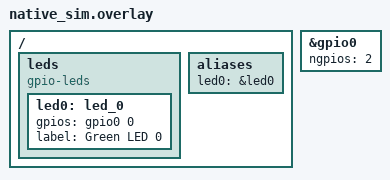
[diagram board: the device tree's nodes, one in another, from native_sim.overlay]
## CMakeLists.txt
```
cmake_minimum_required(VERSION 3.20.0)

find_package(Zephyr REQUIRED HINTS $ENV{ZEPHYR_BASE})
project(led_thread_test)

# add location_module (the unit under test)
target_sources(app
    PRIVATE 
    ../../../app/src/modules/led/led_thread.c
    ../../../app/src/common/zbus_channels.c
)

zephyr_include_directories(${ZEPHYR_BASE}/include/zephyr/)
zephyr_include_directories(${ZEPHYR_BASE}/subsys/testsuite/include)
target_include_directories(app PRIVATE ../../../app/src/common)

target_link_options(app PRIVATE --whole-archive)
# Options that cannot be passed through Kconfig fragments
target_compile_definitions(app PRIVATE
	-DCONFIG_APP_LED_LOG_LEVEL=4
	-DCONFIG_APP_LED_THREAD_STACK_SIZE=1024
	-DCONFIG_APP_LED_MSGQ_SIZE=5
	-DCONFIG_APP_LED_WATCHDOG_TIMEOUT_SECONDS=10
	-DCONFIG_APP_LED_MSGQ_TIMEOUT_SECONDS=5
)

# add test file
target_sources(app PRIVATE src/test_led_thread.c)
```

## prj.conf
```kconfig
#
# Copyright (c) 2022 Nordic Semiconductor ASA
#
# SPDX-License-Identifier: LicenseRef-Nordic-5-Clause
#
CONFIG_ZTEST=y

# Task Watchdog
CONFIG_TASK_WDT=y
CONFIG_TASK_WDT_CHANNELS=5
CONFIG_TASK_WDT_MIN_TIMEOUT=10000

# Configure Zbus
CONFIG_ZBUS=y
CONFIG_ZBUS_LOG_LEVEL_DBG=y

# Configure Emulation
CONFIG_EMUL=y
CONFIG_GPIO=y
CONFIG_GPIO_EMUL=y
CONFIG_GPIO_GET_DIRECTION=y

# Configure Logging
CONFIG_LOG=y
CONFIG_ASSERT=y
CONFIG_BOOT_BANNER=n
```

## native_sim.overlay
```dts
/*
 * Copyright (c) 2021 Nordic Semiconductor ASA
 * SPDX-License-Identifier: Apache-2.0
 */

/* This devicetree overlay file will be automatically picked by the Zephyr
 * build system when building the sample for the nrf52840dk board. It shows
 * how the example-application can be built on sample boards already provided
 * by Zephyr.
 */

/ {
    leds {
		compatible = "gpio-leds";
		led0: led_0 {
			gpios = <&gpio0 0 GPIO_ACTIVE_HIGH>;
			label = "Green LED 0";
		};
	};

    aliases {
		led0 = &led0;
	};
};

&gpio0 {
	status = "okay";
	ngpios = <2>;
};
```

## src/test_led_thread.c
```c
#include <zephyr/irq_offload.h>
#include <zephyr/kernel.h>
#include <zephyr/logging/log.h>
#include <zephyr/zbus/zbus.h>
#include <zephyr/ztest.h>
#include <zephyr/drivers/gpio/gpio_emul.h>

#include "zbus_channels.h"

LOG_MODULE_REGISTER( test_led_thread, LOG_LEVEL_DBG );

// The devicetree node identifier for the "led0" alias.
#define LED0_NODE DT_ALIAS( led0 )
#if !DT_NODE_HAS_STATUS_OKAY( LED0_NODE )
#error "Unsupported board: led0 devicetree alias is not defined"
#endif
static const struct gpio_dt_spec led = GPIO_DT_SPEC_GET( LED0_NODE, gpios );

ZTEST( integration, test_button_press )
{
    struct button_msg button_message = { .press = BUTTON_PRESS };
    int               gpio_val       = -1;

    // Wait for the led to be configured as an output by the thread under test
    while( gpio_pin_is_output_dt( &led ) == 0 )
    {
        k_sleep( K_MSEC( 10 ) );
    }

    // Simulate a button press by publishing to the channel and check the LED value
    zbus_chan_pub( &BUTTON_CHAN, &button_message, K_FOREVER );
    k_sleep( K_MSEC( 100 ) );
    gpio_val = gpio_emul_output_get( led.port, led.pin );
    zassert_equal( gpio_val, 1, "LED state should be ON (1), observed (%d)", gpio_val );
}

ZTEST( integration, test_button_release )
{
    struct button_msg button_message = { .press = BUTTON_RELEASE };
    int               gpio_val       = -1;

    // Wait for the led to be configured as an output by the thread under test
    while( gpio_pin_is_output_dt( &led ) == 0 )
    {
        k_sleep( K_MSEC( 10 ) );
    }

    // Simulate a button press by publishing to the channel and check the LED value
    zbus_chan_pub( &BUTTON_CHAN, &button_message, K_FOREVER );
    k_sleep( K_MSEC( 100 ) );
    gpio_val = gpio_emul_output_get( led.port, led.pin );
    zassert_equal( gpio_val, 0, "LED state should be OFF (0), observed (%d)", gpio_val );
}

ZTEST_SUITE( integration, NULL, NULL, NULL, NULL, NULL );
```
